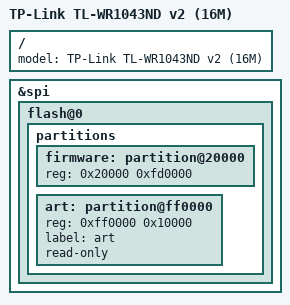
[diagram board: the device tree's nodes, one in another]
// SPDX-License-Identifier: GPL-2.0-or-later OR MIT
/dts-v1/;

#include "qca9558_tplink_tl-wr1043nd-v2.dts"

/ {
	model = "TP-Link TL-WR1043ND v2 (16M)";
};

&spi {
	flash@0 {
		partitions {
			firmware: partition@20000 {
				reg = <0x20000 0xfd0000>;
			};

			/delete-node/ partition@7f0000;
			art: partition@ff0000 {
				reg = <0xff0000 0x10000>;
				label = "art";
				read-only;
			};
		};
	};
};
